AUTOSAR XML (schema 00046)
package /Runnable_Lab2
  sender receiver interface Get_Paramaters
    data Var1: type=uint16
    data Var2: type=uint16
  sender receiver interface Get_Result
    data Result: type=uint32
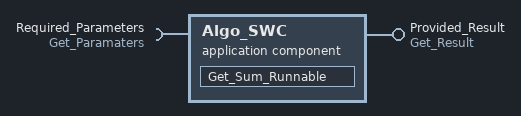
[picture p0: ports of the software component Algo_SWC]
  application sw component type Algo_SWC
    require port Required_Parameters: required-interface=Get_Paramaters
    provide port Provided_Result: provided-interface=Get_Result
    behavior SWC_Beh
      runnable Get_Sum_Runnable: symbol=GetSum
        data-read-access:
          access Variable1: accessed-variable=Required_Parameters.Var1
          access Variable2: accessed-variable=Required_Parameters.Var2
        data-write-access:
          access Result: accessed-variable=Provided_Result.Result
